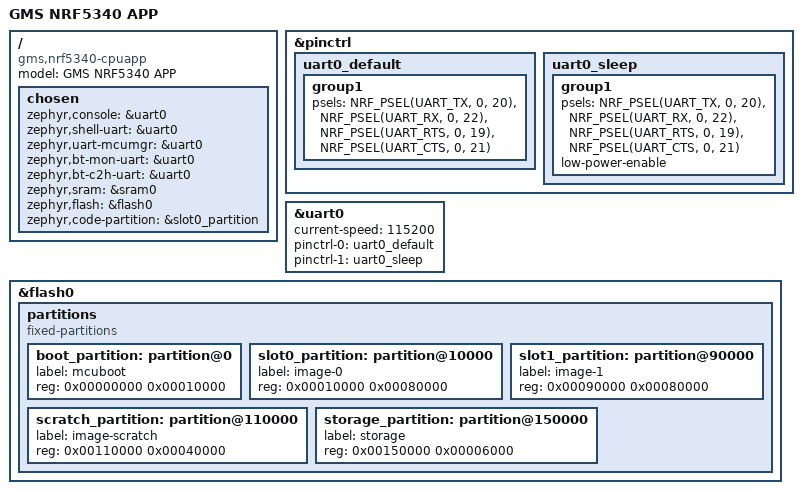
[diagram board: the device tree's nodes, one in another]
/dts-v1/;
#include <nordic/nrf5340_cpuapp_qkaa.dtsi>
#include "gms_nrf5340_cpuapp-pinctrl.dtsi"

/ {
    model = "GMS NRF5340 APP";
    compatible = "gms,nrf5340-cpuapp";

    chosen {
        zephyr,console = &uart0;
        zephyr,shell-uart = &uart0;
        zephyr,uart-mcumgr = &uart0;
        zephyr,bt-mon-uart = &uart0;
        zephyr,bt-c2h-uart = &uart0;
        zephyr,sram = &sram0;
        zephyr,flash = &flash0;
        zephyr,code-partition = &slot0_partition;
    };
};

&pinctrl {
    uart0_default: uart0_default {
        group1 {
            psels = <NRF_PSEL(UART_TX, 0, 20)>,
                    <NRF_PSEL(UART_RX, 0, 22)>,
                    <NRF_PSEL(UART_RTS, 0, 19)>,
                    <NRF_PSEL(UART_CTS, 0, 21)>;
        };
    };

    uart0_sleep: uart0_sleep {
        group1 {
            psels = <NRF_PSEL(UART_TX, 0, 20)>,
                    <NRF_PSEL(UART_RX, 0, 22)>,
                    <NRF_PSEL(UART_RTS, 0, 19)>,
                    <NRF_PSEL(UART_CTS, 0, 21)>;
            low-power-enable;
        };
    };
};

&uart0 {
    status = "okay";
    current-speed = <115200>;
    pinctrl-0 = <&uart0_default>;
    pinctrl-1 = <&uart0_sleep>;
    pinctrl-names = "default", "sleep";
};

&flash0 {
    partitions {
        compatible = "fixed-partitions";
        #address-cells = <1>;
        #size-cells = <1>;

        boot_partition: partition@0 {
            label = "mcuboot";
            reg = <0x00000000 0x00010000>;
        };
        slot0_partition: partition@10000 {
            label = "image-0";
            reg = <0x00010000 0x00080000>;
        };
        slot1_partition: partition@90000 {
            label = "image-1";
            reg = <0x00090000 0x00080000>;
        };
        scratch_partition: partition@110000 {
            label = "image-scratch";
            reg = <0x00110000 0x00040000>;
        };
        storage_partition: partition@150000 {
            label = "storage";
            reg = <0x00150000 0x00006000>;
        };
    };
};
